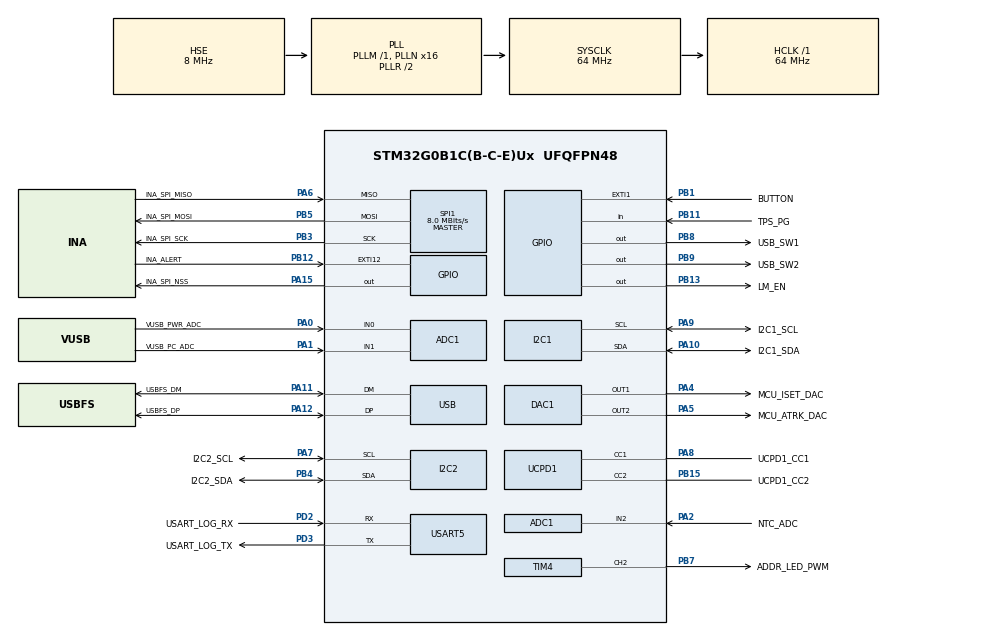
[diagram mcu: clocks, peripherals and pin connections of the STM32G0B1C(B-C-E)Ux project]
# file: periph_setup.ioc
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ADC1.Channel-0\#ChannelRegularConversion=ADC_CHANNEL_0
ADC1.NbrOfConversion=1
ADC1.NbrOfConversionFlag=1
ADC1.Rank-0\#ChannelRegularConversion=1
ADC1.SamplingTime-0\#ChannelRegularConversion=ADC_SAMPLINGTIME_COMMON_1
ADC1.SamplingTimeCommon1=ADC_SAMPLETIME_79CYCLES_5
ADC1.SamplingTimeCommon2=ADC_SAMPLETIME_79CYCLES_5
ADC1.SelectedChannel=ADC_CHANNEL_0|ADC_CHANNEL_1|ADC_CHANNEL_2|ADC_CHANNEL_VREFINT
ADC1.master=1
DAC1.DAC_Channel-DAC_OUT1=DAC_CHANNEL_1
DAC1.DAC_Channel-DAC_OUT2=DAC_CHANNEL_2
Dma.Request0=UCPD1_RX
Dma.Request1=UCPD1_TX
Dma.Request2=TIM4_CH2
Dma.TIM4_CH2.2.Direction=DMA_MEMORY_TO_PERIPH
Dma.TIM4_CH2.2.EventEnable=DISABLE
Dma.TIM4_CH2.2.Instance=DMA1_Channel1
Dma.TIM4_CH2.2.MemDataAlignment=DMA_MDATAALIGN_BYTE
Dma.TIM4_CH2.2.MemInc=DMA_MINC_ENABLE
Dma.TIM4_CH2.2.Mode=DMA_CIRCULAR
Dma.TIM4_CH2.2.PeriphDataAlignment=DMA_PDATAALIGN_HALFWORD
Dma.TIM4_CH2.2.PeriphInc=DMA_PINC_DISABLE
Dma.TIM4_CH2.2.Polarity=HAL_DMAMUX_REQ_GEN_RISING
Dma.TIM4_CH2.2.Priority=DMA_PRIORITY_LOW
Dma.TIM4_CH2.2.RequestNumber=1
Dma.TIM4_CH2.2.SignalID=NONE
Dma.TIM4_CH2.2.SyncEnable=DISABLE
Dma.TIM4_CH2.2.SyncPolarity=HAL_DMAMUX_SYNC_NO_EVENT
Dma.TIM4_CH2.2.SyncRequestNumber=1
Dma.TIM4_CH2.2.SyncSignalID=NONE
Dma.UCPD1_RX.0.Direction=DMA_PERIPH_TO_MEMORY
Dma.UCPD1_RX.0.EventEnable=DISABLE
Dma.UCPD1_RX.0.Instance=DMA1_Channel3
Dma.UCPD1_RX.0.MemDataAlignment=DMA_MDATAALIGN_BYTE
Dma.UCPD1_RX.0.MemInc=DMA_MINC_ENABLE
Dma.UCPD1_RX.0.Mode=DMA_NORMAL
Dma.UCPD1_RX.0.PeriphDataAlignment=DMA_PDATAALIGN_BYTE
Dma.UCPD1_RX.0.PeriphInc=DMA_PINC_DISABLE
Dma.UCPD1_RX.0.Polarity=HAL_DMAMUX_REQ_GEN_RISING
Dma.UCPD1_RX.0.Priority=DMA_PRIORITY_LOW
Dma.UCPD1_RX.0.RequestNumber=1
Dma.UCPD1_RX.0.SignalID=NONE
Dma.UCPD1_RX.0.SyncEnable=DISABLE
Dma.UCPD1_RX.0.SyncPolarity=HAL_DMAMUX_SYNC_NO_EVENT
Dma.UCPD1_RX.0.SyncRequestNumber=1
Dma.UCPD1_RX.0.SyncSignalID=NONE
Dma.UCPD1_TX.1.Direction=DMA_MEMORY_TO_PERIPH
Dma.UCPD1_TX.1.EventEnable=DISABLE
Dma.UCPD1_TX.1.Instance=DMA1_Channel4
Dma.UCPD1_TX.1.MemDataAlignment=DMA_MDATAALIGN_BYTE
Dma.UCPD1_TX.1.MemInc=DMA_MINC_ENABLE
Dma.UCPD1_TX.1.Mode=DMA_NORMAL
Dma.UCPD1_TX.1.PeriphDataAlignment=DMA_PDATAALIGN_BYTE
Dma.UCPD1_TX.1.PeriphInc=DMA_PINC_DISABLE
Dma.UCPD1_TX.1.Polarity=HAL_DMAMUX_REQ_GEN_RISING
Dma.UCPD1_TX.1.Priority=DMA_PRIORITY_LOW
Dma.UCPD1_TX.1.RequestNumber=1
Dma.UCPD1_TX.1.SignalID=NONE
Dma.UCPD1_TX.1.SyncEnable=DISABLE
Dma.UCPD1_TX.1.SyncPolarity=HAL_DMAMUX_SYNC_NO_EVENT
Dma.UCPD1_TX.1.SyncRequestNumber=1
Dma.UCPD1_TX.1.SyncSignalID=NONE
I2C1.Timing=0x10B17DB5
I2C2.Timing=0x10B17DB5
Mcu.Family=STM32G0
Mcu.Name=STM32G0B1C(B-C-E)Ux
Mcu.Package=UFQFPN48
NVIC.ADC1_COMP_IRQn=true\:0\:0\:false\:false\:true\:true\:true\:true
NVIC.DMA1_Ch4_7_DMA2_Ch1_5_DMAMUX1_OVR_IRQn=true\:0\:0\:false\:false\:true\:false\:true\:true
NVIC.DMA1_Channel1_IRQn=true\:0\:0\:false\:false\:true\:false\:true\:true
NVIC.DMA1_Channel2_3_IRQn=true\:0\:0\:false\:false\:true\:false\:true\:true
NVIC.EXTI0_1_IRQn=true\:0\:0\:false\:false\:true\:true\:true\:true
NVIC.EXTI4_15_IRQn=true\:0\:0\:false\:false\:true\:true\:true\:true
NVIC.I2C1_IRQn=true\:0\:0\:false\:false\:true\:true\:true\:true
NVIC.SPI1_IRQn=true\:0\:0\:false\:false\:true\:true\:true\:true
NVIC.TIM2_IRQn=true\:3\:0\:false\:false\:true\:false\:true\:true
NVIC.TimeBase=TIM2_IRQn
NVIC.TimeBaseIP=TIM2
NVIC.USART3_4_5_6_LPUART1_IRQn=true\:0\:0\:false\:false\:true\:false\:true\:true
NVIC.USB_UCPD1_2_IRQn=true\:0\:0\:false\:false\:true\:true\:false\:true
PA0.GPIO_Label=VUSB_PWR_ADC
PA0.Mode=IN0
PA0.Signal=ADC1_IN0
PA1.GPIO_Label=VUSB_PC_ADC
PA1.Mode=IN1
PA1.Signal=ADC1_IN1
PA10.GPIO_Label=I2C1_SDA
PA10.Mode=I2C
PA10.Signal=I2C1_SDA
PA11\ [PA9].GPIO_Label=USBFS_DM
PA11\ [PA9].Mode=Device
PA11\ [PA9].Signal=USB_DM
PA12\ [PA10].GPIO_Label=USBFS_DP
PA12\ [PA10].Mode=Device
PA12\ [PA10].Signal=USB_DP
PA13.Mode=Serial_Wire
PA13.Signal=SYS_SWDIO
PA14-BOOT0.Mode=Serial_Wire
PA14-BOOT0.Signal=SYS_SWCLK
PA15.GPIO_Label=INA_SPI_NSS
PA15.GPIO_Speed=GPIO_SPEED_FREQ_VERY_HIGH
PA15.PinState=GPIO_PIN_SET
PA15.Signal=GPIO_Output
PA2.GPIO_Label=NTC_ADC
PA2.Mode=IN2
PA2.Signal=ADC1_IN2
PA4.GPIO_Label=MCU_ISET_DAC
PA4.Signal=COMP_DAC11_group
PA5.GPIO_Label=MCU_ATRK_DAC
PA5.Signal=COMP_DAC12_group
PA6.GPIO_Label=INA_SPI_MISO
PA6.GPIO_Speed=GPIO_SPEED_FREQ_VERY_HIGH
PA6.Mode=Full_Duplex_Master
PA6.Signal=SPI1_MISO
PA7.GPIO_Label=I2C2_SCL
PA7.Mode=I2C
PA7.Signal=I2C2_SCL
PA8.GPIO_Label=UCPD1_CC1
PA8.Mode=Sink_AllSignals
PA8.Signal=UCPD1_CC1
PA9.GPIO_Label=I2C1_SCL
PA9.Mode=I2C
PA9.Signal=I2C1_SCL
PB0.GPIO_Label=USART_TRACE_RX
PB0.Signal=USART3_RX
PB1.GPIO_Label=BUTTON
PB1.GPIO_ModeDefaultEXTI=GPIO_MODE_IT_RISING_FALLING
PB1.Signal=GPXTI1
PB11.GPIO_Label=TPS_PG
PB11.Signal=GPIO_Input
PB12.GPIO_Label=INA_ALERT
PB12.GPIO_ModeDefaultEXTI=GPIO_MODE_IT_FALLING
PB12.Signal=GPXTI12
PB13.GPIO_Label=LM_EN
PB13.GPIO_ModeDefaultOutputPP=GPIO_MODE_OUTPUT_OD
PB13.GPIO_PuPd=GPIO_NOPULL
PB13.PinState=GPIO_PIN_RESET
PB13.Signal=GPIO_Output
PB15.GPIO_Label=UCPD1_CC2
PB15.Mode=Sink_AllSignals
PB15.Signal=UCPD1_CC2
PB2.GPIO_Label=USART_TRACE_TX
PB2.Signal=USART3_TX
PB3.GPIO_Label=INA_SPI_SCK
PB3.GPIO_Speed=GPIO_SPEED_FREQ_VERY_HIGH
PB3.Mode=Full_Duplex_Master
PB3.Signal=SPI1_SCK
PB4.GPIO_Label=I2C2_SDA
PB4.Mode=I2C
PB4.Signal=I2C2_SDA
PB5.GPIO_Label=INA_SPI_MOSI
PB5.GPIO_Speed=GPIO_SPEED_FREQ_VERY_HIGH
PB5.Mode=Full_Duplex_Master
PB5.Signal=SPI1_MOSI
PB6.GPIO_Label=DTRK_PWM
PB6.Signal=S_TIM1_CH3
PB7.GPIO_Label=ADDR_LED_PWM
PB7.GPIO_Speed=GPIO_SPEED_FREQ_VERY_HIGH
PB7.Signal=S_TIM4_CH2
PB8.GPIO_Label=USB_SW1
PB8.PinState=GPIO_PIN_SET
PB8.Signal=GPIO_Output
PB9.GPIO_Label=USB_SW2
PB9.PinState=GPIO_PIN_SET
PB9.Signal=GPIO_Output
PC14-OSC32_IN\ (PC14).Mode=LSE-External-Oscillator
PC14-OSC32_IN\ (PC14).Signal=RCC_OSC32_IN
PC15-OSC32_OUT\ (PC15).Mode=LSE-External-Oscillator
PC15-OSC32_OUT\ (PC15).Signal=RCC_OSC32_OUT
PD2.GPIO_Label=USART_LOG_RX
PD2.Mode=Asynchronous
PD2.Signal=USART5_RX
PD3.GPIO_Label=USART_LOG_TX
PD3.Mode=Asynchronous
PD3.Signal=USART5_TX
PF0-OSC_IN\ (PF0).Mode=HSE-External-Oscillator
PF0-OSC_IN\ (PF0).Signal=RCC_OSC_IN
PF1-OSC_OUT\ (PF1).Mode=HSE-External-Oscillator
PF1-OSC_OUT\ (PF1).Signal=RCC_OSC_OUT
ProjectManager.HeapSize=0x200
ProjectManager.StackSize=0x400
ProjectManager.TargetToolchain=CMake
RCC.ADCFreq_Value=64000000
RCC.AHBFreq_Value=64000000
RCC.CortexFreq_Value=64000000
RCC.EXTERNAL_CLOCK_VALUE=48000
RCC.HCLKFreq_Value=64000000
RCC.HSE_VALUE=8000000
RCC.HSI48_VALUE=48000000
RCC.HSI_VALUE=16000000
RCC.PLLN=16
RCC.PLLSourceVirtual=RCC_PLLSOURCE_HSE
RCC.SYSCLKFreq_VALUE=64000000
RCC.SYSCLKSource=RCC_SYSCLKSOURCE_PLLCLK
RCC.USBFreq_Value=48000000
RCC.VCOOutputFreq_Value=128000000
SH.COMP_DAC11_group.0=DAC1_OUT1,DAC_OUT1
SH.COMP_DAC12_group.0=DAC1_OUT2,DAC_OUT2
SH.S_TIM1_CH3.0=TIM1_CH3
SH.S_TIM4_CH2.0=TIM4_CH2,PWM Generation2 CH2
SPI1.BaudRatePrescaler=SPI_BAUDRATEPRESCALER_8
SPI1.CLKPhase=SPI_PHASE_2EDGE
SPI1.CalculateBaudRate=8.0 MBits/s
SPI1.DataSize=SPI_DATASIZE_8BIT
SPI1.Direction=SPI_DIRECTION_2LINES
SPI1.Mode=SPI_MODE_MASTER
SPI1.TIMode=SPI_TIMODE_DISABLE
SPI1.VirtualType=VM_MASTER
TIM4.AutoReloadPreload=TIM_AUTORELOAD_PRELOAD_ENABLE
TIM4.Channel-PWM\ Generation2\ CH2=TIM_CHANNEL_2
TIM4.Period=80-1
USART5.VirtualMode-Asynchronous=VM_ASYNC
VP_ADC1_Vref_Input.Mode=IN-Vrefint
VP_SYS_VS_DBSignals.Mode=DisableDeadBatterySignals
VP_SYS_VS_tim2.Mode=TIM2
VP_SYS_V_VREFBUF.Mode=ExternalMode
VP_TIM4_VS_ClockSourceINT.Mode=Internal
board=custom

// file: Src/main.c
/* USER CODE BEGIN Header */
/**
 ******************************************************************************
 * @file           : main.c
 * @brief          : Main program body
 ******************************************************************************
 * @attention
 *
 * Copyright (c) 2025 STMicroelectronics.
 * All rights reserved.
 *
 * This software is licensed under terms that can be found in the LICENSE file
 * in the root directory of this software component.
 * If no LICENSE file comes with this software, it is provided AS-IS.
 *
 ******************************************************************************
 */
/* USER CODE END Header */
#include "main.h"

/* USER CODE BEGIN Includes */
#include <usbpd_dpm_core.h>

#include "app.h"
/* USER CODE END Includes */

ADC_HandleTypeDef hadc1;

DAC_HandleTypeDef hdac1;

I2C_HandleTypeDef hi2c1;
I2C_HandleTypeDef hi2c2;

SPI_HandleTypeDef hspi1;

TIM_HandleTypeDef htim4;
DMA_HandleTypeDef hdma_tim4_ch2;

UART_HandleTypeDef huart5;

PCD_HandleTypeDef hpcd_USB_DRD_FS;

void        SystemClock_Config(void);
static void MX_GPIO_Init(void);
static void MX_DMA_Init(void);
static void MX_ADC1_Init(void);
static void MX_DAC1_Init(void);
static void MX_I2C1_Init(void);
static void MX_I2C2_Init(void);
static void MX_SPI1_Init(void);
static void MX_TIM4_Init(void);
static void MX_UCPD1_Init(void);
static void MX_USB_DRD_FS_PCD_Init(void);
static void MX_USART5_UART_Init(void);

int main(void)
{

    /* MCU
     * Configuration--------------------------------------------------------*/

    /* Reset of all peripherals, Initializes the Flash interface and the
     * Systick. */
    HAL_Init();

    /* Configure the system clock */
    SystemClock_Config();

    /* Initialize all configured peripherals */
    MX_GPIO_Init();
    MX_DMA_Init();
    MX_ADC1_Init();
    MX_DAC1_Init();
    MX_I2C1_Init();
    MX_I2C2_Init();
    MX_SPI1_Init();
    MX_TIM4_Init();
    MX_UCPD1_Init();
    MX_USB_DRD_FS_PCD_Init();
    MX_USART5_UART_Init();
    /* USER CODE BEGIN 2 */

    // Enable DAC_CH1
    HAL_DAC_Start(&hdac1, DAC_CHANNEL_1);

    app();
    /* USER CODE END 2 */

    /* Infinite loop */
    while (1) {

    }
}

void SystemClock_Config(void)
{
    RCC_OscInitTypeDef RCC_OscInitStruct = {0};
    RCC_ClkInitTypeDef RCC_ClkInitStruct = {0};

    /** Configure the main internal regulator output voltage
     */
    HAL_PWREx_ControlVoltageScaling(PWR_REGULATOR_VOLTAGE_SCALE1);

    /** Initializes the RCC Oscillators according to the specified parameters
     * in the RCC_OscInitTypeDef structure.
     */
    RCC_OscInitStruct.OscillatorType = RCC_OSCILLATORTYPE_HSI |
                                       RCC_OSCILLATORTYPE_HSE |
                                       RCC_OSCILLATORTYPE_HSI48;
    RCC_OscInitStruct.HSEState            = RCC_HSE_ON;
    RCC_OscInitStruct.HSIState            = RCC_HSI_ON;
    RCC_OscInitStruct.HSI48State          = RCC_HSI48_ON;
    RCC_OscInitStruct.HSIDiv              = RCC_HSI_DIV1;
    RCC_OscInitStruct.HSICalibrationValue = RCC_HSICALIBRATION_DEFAULT;
    RCC_OscInitStruct.PLL.PLLState        = RCC_PLL_ON;
    RCC_OscInitStruct.PLL.PLLSource       = RCC_PLLSOURCE_HSE;
    RCC_OscInitStruct.PLL.PLLM            = RCC_PLLM_DIV1;
    RCC_OscInitStruct.PLL.PLLN            = 16;
    RCC_OscInitStruct.PLL.PLLP            = RCC_PLLP_DIV2;
    RCC_OscInitStruct.PLL.PLLQ            = RCC_PLLQ_DIV2;
    RCC_OscInitStruct.PLL.PLLR            = RCC_PLLR_DIV2;
    if (HAL_RCC_OscConfig(&RCC_OscInitStruct) != HAL_OK) {
        Error_Handler();
    }

    /** Initializes the CPU, AHB and APB buses clocks
     */
    RCC_ClkInitStruct.ClockType =
        RCC_CLOCKTYPE_HCLK | RCC_CLOCKTYPE_SYSCLK | RCC_CLOCKTYPE_PCLK1;
    RCC_ClkInitStruct.SYSCLKSource   = RCC_SYSCLKSOURCE_PLLCLK;
    RCC_ClkInitStruct.AHBCLKDivider  = RCC_SYSCLK_DIV1;
    RCC_ClkInitStruct.APB1CLKDivider = RCC_HCLK_DIV1;

    if (HAL_RCC_ClockConfig(&RCC_ClkInitStruct, FLASH_LATENCY_2) != HAL_OK) {
        Error_Handler();
    }
}

static void MX_ADC1_Init(void)
{

    ADC_ChannelConfTypeDef sConfig = {0};

    /** Configure the global features of the ADC (Clock, Resolution, Data
     * Alignment and number of conversion)
     */
    hadc1.Instance                   = ADC1;
    hadc1.Init.ClockPrescaler        = ADC_CLOCK_SYNC_PCLK_DIV2;
    hadc1.Init.Resolution            = ADC_RESOLUTION_12B;
    hadc1.Init.DataAlign             = ADC_DATAALIGN_RIGHT;
    hadc1.Init.ScanConvMode          = ADC_SCAN_DISABLE;
    hadc1.Init.EOCSelection          = ADC_EOC_SINGLE_CONV;
    hadc1.Init.LowPowerAutoWait      = DISABLE;
    hadc1.Init.LowPowerAutoPowerOff  = DISABLE;
    hadc1.Init.ContinuousConvMode    = DISABLE;
    hadc1.Init.NbrOfConversion       = 1;
    hadc1.Init.DiscontinuousConvMode = DISABLE;
    hadc1.Init.ExternalTrigConv      = ADC_SOFTWARE_START;
    hadc1.Init.ExternalTrigConvEdge  = ADC_EXTERNALTRIGCONVEDGE_NONE;
    hadc1.Init.DMAContinuousRequests = DISABLE;
    hadc1.Init.Overrun               = ADC_OVR_DATA_PRESERVED;
    hadc1.Init.SamplingTimeCommon1   = ADC_SAMPLETIME_79CYCLES_5;
    hadc1.Init.SamplingTimeCommon2   = ADC_SAMPLETIME_79CYCLES_5;
    hadc1.Init.OversamplingMode      = DISABLE;
    hadc1.Init.TriggerFrequencyMode  = ADC_TRIGGER_FREQ_HIGH;
    if (HAL_ADC_Init(&hadc1) != HAL_OK) {
        Error_Handler();
    }

    /** Configure Regular Channel
     */
    sConfig.Channel      = ADC_CHANNEL_0;
    sConfig.Rank         = ADC_REGULAR_RANK_1;
    sConfig.SamplingTime = ADC_SAMPLINGTIME_COMMON_1;
    if (HAL_ADC_ConfigChannel(&hadc1, &sConfig) != HAL_OK) {
        Error_Handler();
    }
}

static void MX_DAC1_Init(void)
{

    DAC_ChannelConfTypeDef sConfig = {0};

    /** DAC Initialization
     */
    hdac1.Instance = DAC1;
    if (HAL_DAC_Init(&hdac1) != HAL_OK) {
        Error_Handler();
    }

    /** DAC channel OUT1 config
     */
    sConfig.DAC_SampleAndHold           = DAC_SAMPLEANDHOLD_DISABLE;
    sConfig.DAC_Trigger                 = DAC_TRIGGER_NONE;
    sConfig.DAC_OutputBuffer            = DAC_OUTPUTBUFFER_ENABLE;
    sConfig.DAC_ConnectOnChipPeripheral = DAC_CHIPCONNECT_DISABLE;
    sConfig.DAC_UserTrimming            = DAC_TRIMMING_FACTORY;
    if (HAL_DAC_ConfigChannel(&hdac1, &sConfig, DAC_CHANNEL_1) != HAL_OK) {
        Error_Handler();
    }

    /** DAC channel OUT2 config
     */
    if (HAL_DAC_ConfigChannel(&hdac1, &sConfig, DAC_CHANNEL_2) != HAL_OK) {
        Error_Handler();
    }
}

static void MX_I2C1_Init(void)
{

    hi2c1.Instance              = I2C1;
    hi2c1.Init.Timing           = 0x10B17DB5;
    hi2c1.Init.OwnAddress1      = 0;
    hi2c1.Init.AddressingMode   = I2C_ADDRESSINGMODE_7BIT;
    hi2c1.Init.DualAddressMode  = I2C_DUALADDRESS_DISABLE;
    hi2c1.Init.OwnAddress2      = 0;
    hi2c1.Init.OwnAddress2Masks = I2C_OA2_NOMASK;
    hi2c1.Init.GeneralCallMode  = I2C_GENERALCALL_DISABLE;
    hi2c1.Init.NoStretchMode    = I2C_NOSTRETCH_DISABLE;
    if (HAL_I2C_Init(&hi2c1) != HAL_OK) {
        Error_Handler();
    }

    /** Configure Analogue filter
     */
    if (HAL_I2CEx_ConfigAnalogFilter(&hi2c1, I2C_ANALOGFILTER_ENABLE) !=
        HAL_OK) {
        Error_Handler();
    }

    /** Configure Digital filter
     */
    if (HAL_I2CEx_ConfigDigitalFilter(&hi2c1, 0) != HAL_OK) {
        Error_Handler();
    }
}

static void MX_I2C2_Init(void)
{

    hi2c2.Instance              = I2C2;
    hi2c2.Init.Timing           = 0x10B17DB5;
    hi2c2.Init.OwnAddress1      = 0;
    hi2c2.Init.AddressingMode   = I2C_ADDRESSINGMODE_7BIT;
    hi2c2.Init.DualAddressMode  = I2C_DUALADDRESS_DISABLE;
    hi2c2.Init.OwnAddress2      = 0;
    hi2c2.Init.OwnAddress2Masks = I2C_OA2_NOMASK;
    hi2c2.Init.GeneralCallMode  = I2C_GENERALCALL_DISABLE;
    hi2c2.Init.NoStretchMode    = I2C_NOSTRETCH_DISABLE;
    if (HAL_I2C_Init(&hi2c2) != HAL_OK) {
        Error_Handler();
    }

    /** Configure Analogue filter
     */
    if (HAL_I2CEx_ConfigAnalogFilter(&hi2c2, I2C_ANALOGFILTER_ENABLE) !=
        HAL_OK) {
        Error_Handler();
    }

    /** Configure Digital filter
     */
    if (HAL_I2CEx_ConfigDigitalFilter(&hi2c2, 0) != HAL_OK) {
        Error_Handler();
    }
}

static void MX_SPI1_Init(void)
{

    /* SPI1 parameter configuration*/
    hspi1.Instance               = SPI1;
    hspi1.Init.Mode              = SPI_MODE_MASTER;
    hspi1.Init.Direction         = SPI_DIRECTION_2LINES;
    hspi1.Init.DataSize          = SPI_DATASIZE_8BIT;
    hspi1.Init.CLKPolarity       = SPI_POLARITY_LOW;
    hspi1.Init.CLKPhase          = SPI_PHASE_2EDGE;
    hspi1.Init.NSS               = SPI_NSS_SOFT;
    hspi1.Init.BaudRatePrescaler = SPI_BAUDRATEPRESCALER_8;
    hspi1.Init.FirstBit          = SPI_FIRSTBIT_MSB;
    hspi1.Init.TIMode            = SPI_TIMODE_DISABLE;
    hspi1.Init.CRCCalculation    = SPI_CRCCALCULATION_DISABLE;
    hspi1.Init.CRCPolynomial     = 7;
    hspi1.Init.CRCLength         = SPI_CRC_LENGTH_DATASIZE;
    hspi1.Init.NSSPMode          = SPI_NSS_PULSE_DISABLE;
    if (HAL_SPI_Init(&hspi1) != HAL_OK) {
        Error_Handler();
    }
}

static void MX_TIM4_Init(void)
{

    TIM_ClockConfigTypeDef  sClockSourceConfig = {0};
    TIM_MasterConfigTypeDef sMasterConfig      = {0};
    TIM_OC_InitTypeDef      sConfigOC          = {0};

    htim4.Instance               = TIM4;
    htim4.Init.Prescaler         = 0;
    htim4.Init.CounterMode       = TIM_COUNTERMODE_UP;
    htim4.Init.Period            = 80 - 1;
    htim4.Init.ClockDivision     = TIM_CLOCKDIVISION_DIV1;
    htim4.Init.AutoReloadPreload = TIM_AUTORELOAD_PRELOAD_ENABLE;
    if (HAL_TIM_Base_Init(&htim4) != HAL_OK) {
        Error_Handler();
    }
    sClockSourceConfig.ClockSource = TIM_CLOCKSOURCE_INTERNAL;
    if (HAL_TIM_ConfigClockSource(&htim4, &sClockSourceConfig) != HAL_OK) {
        Error_Handler();
    }
    if (HAL_TIM_PWM_Init(&htim4) != HAL_OK) {
        Error_Handler();
    }
    sMasterConfig.MasterOutputTrigger = TIM_TRGO_RESET;
    sMasterConfig.MasterSlaveMode     = TIM_MASTERSLAVEMODE_DISABLE;
    if (HAL_TIMEx_MasterConfigSynchronization(&htim4, &sMasterConfig) !=
        HAL_OK) {
        Error_Handler();
    }
    sConfigOC.OCMode     = TIM_OCMODE_PWM1;
    sConfigOC.Pulse      = 0;
    sConfigOC.OCPolarity = TIM_OCPOLARITY_HIGH;
    sConfigOC.OCFastMode = TIM_OCFAST_DISABLE;
    if (HAL_TIM_PWM_ConfigChannel(&htim4, &sConfigOC, TIM_CHANNEL_2) !=
        HAL_OK) {
        Error_Handler();
    }
    HAL_TIM_MspPostInit(&htim4);
}

static void MX_UCPD1_Init(void)
{

    LL_GPIO_InitTypeDef GPIO_InitStruct = {0};

    /* Peripheral clock enable */
    LL_APB1_GRP1_EnableClock(LL_APB1_GRP1_PERIPH_UCPD1);

    LL_IOP_GRP1_EnableClock(LL_IOP_GRP1_PERIPH_GPIOB);
    LL_IOP_GRP1_EnableClock(LL_IOP_GRP1_PERIPH_GPIOA);
    /**UCPD1 GPIO Configuration
    PB15   ------> UCPD1_CC2
    PA8   ------> UCPD1_CC1
    */
    GPIO_InitStruct.Pin  = LL_GPIO_PIN_15;
    GPIO_InitStruct.Mode = LL_GPIO_MODE_ANALOG;
    GPIO_InitStruct.Pull = LL_GPIO_PULL_NO;
    LL_GPIO_Init(GPIOB, &GPIO_InitStruct);

    GPIO_InitStruct.Pin  = LL_GPIO_PIN_8;
    GPIO_InitStruct.Mode = LL_GPIO_MODE_ANALOG;
    GPIO_InitStruct.Pull = LL_GPIO_PULL_NO;
    LL_GPIO_Init(GPIOA, &GPIO_InitStruct);

    /* UCPD1 DMA Init */

    /* UCPD1_RX Init */
    LL_DMA_SetPeriphRequest(DMA1, LL_DMA_CHANNEL_3, LL_DMAMUX_REQ_UCPD1_RX);

    LL_DMA_SetDataTransferDirection(
        DMA1, LL_DMA_CHANNEL_3, LL_DMA_DIRECTION_PERIPH_TO_MEMORY
    );

    LL_DMA_SetChannelPriorityLevel(DMA1, LL_DMA_CHANNEL_3, LL_DMA_PRIORITY_LOW);

    LL_DMA_SetMode(DMA1, LL_DMA_CHANNEL_3, LL_DMA_MODE_NORMAL);

    LL_DMA_SetPeriphIncMode(DMA1, LL_DMA_CHANNEL_3, LL_DMA_PERIPH_NOINCREMENT);

    LL_DMA_SetMemoryIncMode(DMA1, LL_DMA_CHANNEL_3, LL_DMA_MEMORY_INCREMENT);

    LL_DMA_SetPeriphSize(DMA1, LL_DMA_CHANNEL_3, LL_DMA_PDATAALIGN_BYTE);

    LL_DMA_SetMemorySize(DMA1, LL_DMA_CHANNEL_3, LL_DMA_MDATAALIGN_BYTE);

    /* UCPD1_TX Init */
    LL_DMA_SetPeriphRequest(DMA1, LL_DMA_CHANNEL_4, LL_DMAMUX_REQ_UCPD1_TX);

    LL_DMA_SetDataTransferDirection(
        DMA1, LL_DMA_CHANNEL_4, LL_DMA_DIRECTION_MEMORY_TO_PERIPH
    );

    LL_DMA_SetChannelPriorityLevel(DMA1, LL_DMA_CHANNEL_4, LL_DMA_PRIORITY_LOW);

    LL_DMA_SetMode(DMA1, LL_DMA_CHANNEL_4, LL_DMA_MODE_NORMAL);

    LL_DMA_SetPeriphIncMode(DMA1, LL_DMA_CHANNEL_4, LL_DMA_PERIPH_NOINCREMENT);

    LL_DMA_SetMemoryIncMode(DMA1, LL_DMA_CHANNEL_4, LL_DMA_MEMORY_INCREMENT);

    LL_DMA_SetPeriphSize(DMA1, LL_DMA_CHANNEL_4, LL_DMA_PDATAALIGN_BYTE);

    LL_DMA_SetMemorySize(DMA1, LL_DMA_CHANNEL_4, LL_DMA_MDATAALIGN_BYTE);

    /* UCPD1 interrupt Init */
    NVIC_SetPriority(USB_UCPD1_2_IRQn, 0);
    NVIC_EnableIRQ(USB_UCPD1_2_IRQn);

}

static void MX_USART5_UART_Init(void)
{

    huart5.Instance                    = USART5;
    huart5.Init.BaudRate               = 115200;
    huart5.Init.WordLength             = UART_WORDLENGTH_8B;
    huart5.Init.StopBits               = UART_STOPBITS_1;
    huart5.Init.Parity                 = UART_PARITY_NONE;
    huart5.Init.Mode                   = UART_MODE_TX_RX;
    huart5.Init.HwFlowCtl              = UART_HWCONTROL_NONE;
    huart5.Init.OverSampling           = UART_OVERSAMPLING_16;
    huart5.Init.OneBitSampling         = UART_ONE_BIT_SAMPLE_DISABLE;
    huart5.Init.ClockPrescaler         = UART_PRESCALER_DIV1;
    huart5.AdvancedInit.AdvFeatureInit = UART_ADVFEATURE_NO_INIT;
    if (HAL_UART_Init(&huart5) != HAL_OK) {
        Error_Handler();
    }
}

static void MX_USB_DRD_FS_PCD_Init(void)
{

    hpcd_USB_DRD_FS.Instance                      = USB_DRD_FS;
    hpcd_USB_DRD_FS.Init.dev_endpoints            = 8;
    hpcd_USB_DRD_FS.Init.Host_channels            = 8;
    hpcd_USB_DRD_FS.Init.speed                    = PCD_SPEED_FULL;
    hpcd_USB_DRD_FS.Init.phy_itface               = PCD_PHY_EMBEDDED;
    hpcd_USB_DRD_FS.Init.Sof_enable               = DISABLE;
    hpcd_USB_DRD_FS.Init.low_power_enable         = DISABLE;
    hpcd_USB_DRD_FS.Init.lpm_enable               = DISABLE;
    hpcd_USB_DRD_FS.Init.battery_charging_enable  = DISABLE;
    hpcd_USB_DRD_FS.Init.vbus_sensing_enable      = DISABLE;
    hpcd_USB_DRD_FS.Init.bulk_doublebuffer_enable = DISABLE;
    hpcd_USB_DRD_FS.Init.iso_singlebuffer_enable  = DISABLE;
    if (HAL_PCD_Init(&hpcd_USB_DRD_FS) != HAL_OK) {
        Error_Handler();
    }
}

static void MX_DMA_Init(void)
{

    /* DMA controller clock enable */
    __HAL_RCC_DMA1_CLK_ENABLE();

    /* DMA interrupt init */
    /* DMA1_Channel1_IRQn interrupt configuration */
    HAL_NVIC_SetPriority(DMA1_Channel1_IRQn, 0, 0);
    HAL_NVIC_EnableIRQ(DMA1_Channel1_IRQn);
    /* DMA1_Channel2_3_IRQn interrupt configuration */
    NVIC_SetPriority(DMA1_Channel2_3_IRQn, 0);
    NVIC_EnableIRQ(DMA1_Channel2_3_IRQn);
    /* DMA1_Ch4_7_DMA2_Ch1_5_DMAMUX1_OVR_IRQn interrupt configuration */
    HAL_NVIC_SetPriority(DMA1_Ch4_7_DMA2_Ch1_5_DMAMUX1_OVR_IRQn, 0, 0);
    HAL_NVIC_EnableIRQ(DMA1_Ch4_7_DMA2_Ch1_5_DMAMUX1_OVR_IRQn);
}

static void MX_GPIO_Init(void)
{
    GPIO_InitTypeDef GPIO_InitStruct = {0};

    /* GPIO Ports Clock Enable */
    __HAL_RCC_GPIOC_CLK_ENABLE();
    __HAL_RCC_GPIOF_CLK_ENABLE();
    __HAL_RCC_GPIOA_CLK_ENABLE();
    __HAL_RCC_GPIOB_CLK_ENABLE();
    __HAL_RCC_GPIOD_CLK_ENABLE();

    /*Configure GPIO pin Output Level */
    HAL_GPIO_WritePin(LM_EN_GPIO_Port, LM_EN_Pin, GPIO_PIN_RESET);

    /*Configure GPIO pin Output Level */
    HAL_GPIO_WritePin(INA_SPI_NSS_GPIO_Port, INA_SPI_NSS_Pin, GPIO_PIN_SET);

    /*Configure GPIO pin Output Level */
    HAL_GPIO_WritePin(GPIOB, USB_SW1_Pin | USB_SW2_Pin, GPIO_PIN_SET);

    /*Configure GPIO pins : USART_TRACE_RX_Pin USART_TRACE_TX_Pin */
    GPIO_InitStruct.Pin       = USART_TRACE_RX_Pin | USART_TRACE_TX_Pin;
    GPIO_InitStruct.Mode      = GPIO_MODE_AF_PP;
    GPIO_InitStruct.Pull      = GPIO_NOPULL;
    GPIO_InitStruct.Speed     = GPIO_SPEED_FREQ_LOW;
    GPIO_InitStruct.Alternate = GPIO_AF4_USART3;
    HAL_GPIO_Init(GPIOB, &GPIO_InitStruct);

    /*Configure GPIO pin : BUTTON_Pin */
    GPIO_InitStruct.Pin  = BUTTON_Pin;
    GPIO_InitStruct.Mode = GPIO_MODE_IT_RISING_FALLING;
    GPIO_InitStruct.Pull = GPIO_NOPULL;
    HAL_GPIO_Init(BUTTON_GPIO_Port, &GPIO_InitStruct);

    /*Configure GPIO pin : TPS_PG_Pin */
    GPIO_InitStruct.Pin  = TPS_PG_Pin;
    GPIO_InitStruct.Mode = GPIO_MODE_INPUT;
    GPIO_InitStruct.Pull = GPIO_NOPULL;
    HAL_GPIO_Init(TPS_PG_GPIO_Port, &GPIO_InitStruct);

    /*Configure GPIO pin : INA_ALERT_Pin */
    GPIO_InitStruct.Pin  = INA_ALERT_Pin;
    GPIO_InitStruct.Mode = GPIO_MODE_IT_FALLING;
    GPIO_InitStruct.Pull = GPIO_NOPULL;
    HAL_GPIO_Init(INA_ALERT_GPIO_Port, &GPIO_InitStruct);

    /*Configure GPIO pin : LM_EN_Pin */
    GPIO_InitStruct.Pin   = LM_EN_Pin;
    GPIO_InitStruct.Mode  = GPIO_MODE_OUTPUT_OD;
    GPIO_InitStruct.Pull  = GPIO_NOPULL;
    GPIO_InitStruct.Speed = GPIO_SPEED_FREQ_LOW;
    HAL_GPIO_Init(LM_EN_GPIO_Port, &GPIO_InitStruct);

    /*Configure GPIO pin : INA_SPI_NSS_Pin */
    GPIO_InitStruct.Pin   = INA_SPI_NSS_Pin;
    GPIO_InitStruct.Mode  = GPIO_MODE_OUTPUT_PP;
    GPIO_InitStruct.Pull  = GPIO_NOPULL;
    GPIO_InitStruct.Speed = GPIO_SPEED_FREQ_VERY_HIGH;
    HAL_GPIO_Init(INA_SPI_NSS_GPIO_Port, &GPIO_InitStruct);

    /*Configure GPIO pin : DTRK_PWM_Pin */
    GPIO_InitStruct.Pin       = DTRK_PWM_Pin;
    GPIO_InitStruct.Mode      = GPIO_MODE_AF_PP;
    GPIO_InitStruct.Pull      = GPIO_NOPULL;
    GPIO_InitStruct.Speed     = GPIO_SPEED_FREQ_LOW;
    GPIO_InitStruct.Alternate = GPIO_AF1_TIM1;
    HAL_GPIO_Init(DTRK_PWM_GPIO_Port, &GPIO_InitStruct);

    /*Configure GPIO pins : USB_SW1_Pin USB_SW2_Pin */
    GPIO_InitStruct.Pin   = USB_SW1_Pin | USB_SW2_Pin;
    GPIO_InitStruct.Mode  = GPIO_MODE_OUTPUT_PP;
    GPIO_InitStruct.Pull  = GPIO_NOPULL;
    GPIO_InitStruct.Speed = GPIO_SPEED_FREQ_LOW;
    HAL_GPIO_Init(GPIOB, &GPIO_InitStruct);

    /* EXTI interrupt init*/
    HAL_NVIC_SetPriority(EXTI0_1_IRQn, 0, 0);
    HAL_NVIC_EnableIRQ(EXTI0_1_IRQn);

    HAL_NVIC_SetPriority(EXTI4_15_IRQn, 0, 0);
    HAL_NVIC_EnableIRQ(EXTI4_15_IRQn);

}

void HAL_TIM_PeriodElapsedCallback(TIM_HandleTypeDef* htim)
{
    if (htim->Instance == TIM2) {
        HAL_IncTick();
    }
    /* USER CODE BEGIN Callback 1 */
    if (htim->Instance == TIM2) {
        USBPD_DPM_TimerCounter();
    }
    /* USER CODE END Callback 1 */
}

void Error_Handler(void)
{
    /* USER CODE BEGIN Error_Handler_Debug */
    /* User can add his own implementation to report the HAL error return state
     */
    __disable_irq();
    while (1) {}
    /* USER CODE END Error_Handler_Debug */
}
#ifdef USE_FULL_ASSERT
/**
 * @brief  Reports the name of the source file and the source line number
 *         where the assert_param error has occurred.
 * @param  file: pointer to the source file name
 * @param  line: assert_param error line source number
 * @retval None
 */
void assert_failed(uint8_t* file, uint32_t line)
{
    /* USER CODE BEGIN 6 */
    /* User can add his own implementation to report the file name and line
       number, ex: printf("Wrong parameters value: file %s on line %d\r\n",
       file, line) */
    /* USER CODE END 6 */
}
#endif /* USE_FULL_ASSERT */
